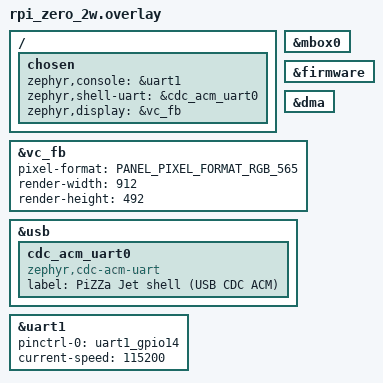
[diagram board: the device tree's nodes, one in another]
/*
 * SPDX-License-Identifier: AGPL-3.0-or-later
 *
 * PiZZa Jet demo overlay for rpi_zero_2w.
 *
 *   - &mailbox + &firmware: VC property-tag mailbox + framebuffer alloc
 *   - &vc_fb: HDMI framebuffer at the monitor's native resolution,
 *     16 bpp RGB565 so Jet's render buffer is the scanout buffer
 *     (one memcpy per frame, no per-pixel conversion).
 *   - &usb: single CDC ACM child for the shell, same shape as PizzaShell.
 *   - uart1 (mini-UART): console + LOG_* on GPIO 14/15 at 115200.
 */

#include <zephyr/dt-bindings/display/panel.h>

&mbox0 {
	status = "okay";
};

&firmware {
	status = "okay";
};

/* DMA controller used by bcm2835_fb for the backbuffer->fb blit.
 * The driver claims the first available channel from the mask at
 * init time (no DT wiring on the fb side).
 */
&dma {
	status = "okay";
};

&vc_fb {
	/* No width / height -- driver auto-detects the monitor's native
	 * mode (typically 1824x984) from VC's EDID negotiation at boot.
	 *
	 * render-width / render-height set the virtual framebuffer size.
	 * VC's HVS hardware scaler upscales this to the scanout
	 * resolution -- the CPU paints ~900 KiB per frame instead of
	 * the full 3.5 MiB, ~4x less bandwidth into uncached DRAM.
	 */
	pixel-format = <PANEL_PIXEL_FORMAT_RGB_565>;
	/* 912 x 492 = 1.853 aspect, matches monitor 1824x984 native.
	 * VC HVS scales 2x both dims so the full screen is used with no
	 * pillarbox. 912 * 2 = 1824 bytes = 32-byte aligned so VC returns
	 * pitch == row_bytes (no padding); the FB driver's contiguous-DMA
	 * fast path takes it.
	 */
	render-width = <912>;
	render-height = <492>;
	status = "okay";
};

&usb {
	status = "okay";

	cdc_acm_uart0: cdc_acm_uart0 {
		compatible = "zephyr,cdc-acm-uart";
		label = "PiZZa Jet shell (USB CDC ACM)";
	};
};

/ {
	chosen {
		zephyr,console = &uart1;
		zephyr,shell-uart = &cdc_acm_uart0;
		zephyr,display = &vc_fb;
	};
};

&uart1 {
	pinctrl-names = "default";
	pinctrl-0 = <&uart1_gpio14>;
	status = "okay";
	current-speed = <115200>;
};
